# STM32U59x register map
File version: 0.2
Registers are 32-bit, read-write, reset 0x0 unless marked. A register's access mark holds for its fields unless they carry their own. Offsets are from the block's base; [hi:lo] are bit positions; {n}, {i} and the like mark numbered series.

## GPIOA — General-purpose I/Os
Base 0x42020000
Same registers: SEC_GPIOA 0x52020000
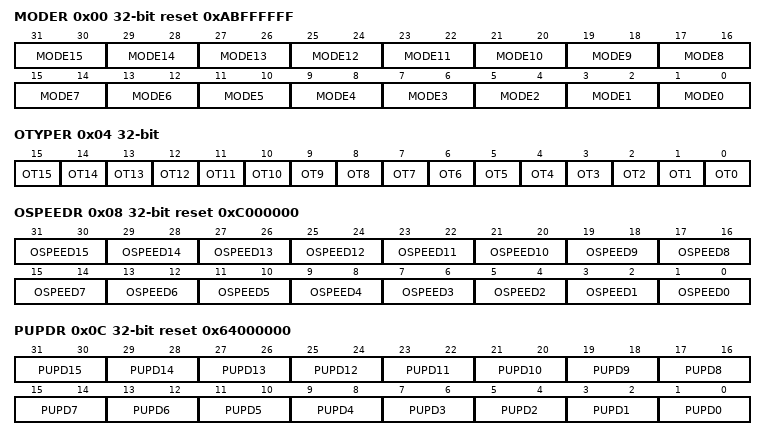
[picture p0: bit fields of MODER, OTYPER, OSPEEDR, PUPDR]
0x00 MODER reset 0xABFFFFFF — GPIO port mode register
  [2n+1:2n] MODE{n} (n=0..15) — Port x configuration bits (y = 0..15)
0x04 OTYPER — GPIO port output type register
  [n] OT{n} (n=0..15) — Port x configuration bits (y = 0..15)
0x08 OSPEEDR reset 0xC000000 — GPIO port output speed register
  [2n+1:2n] OSPEED{n} (n=0..15) — Port x configuration bits (y = 0..15)
0x0C PUPDR reset 0x64000000 — GPIO port pull-up/pull-down register
  [2n+1:2n] PUPD{n} (n=0..15) — Port x configuration bits (y = 0..15)
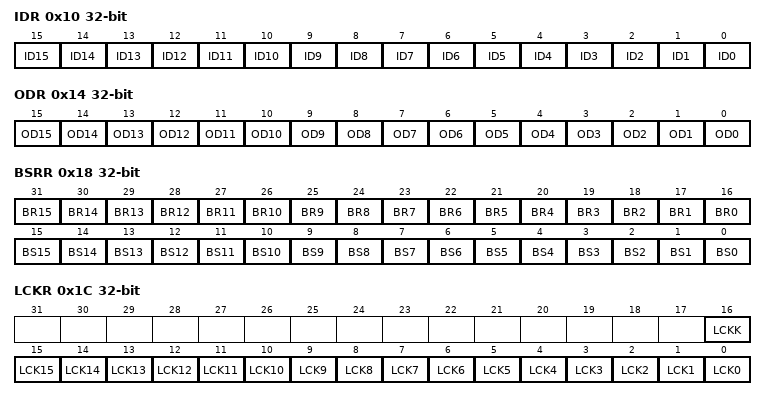
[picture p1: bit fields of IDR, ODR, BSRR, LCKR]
0x10 IDR ro — GPIO port input data register
  [n] ID{n} (n=0..15) — Port input data (y = 0..15)
0x14 ODR — GPIO port output data register
  [n] OD{n} (n=0..15) — Port output data (y = 0..15)
0x18 BSRR wo — GPIO port bit set/reset register
  [n+16] BR{n} (n=1..15) — Port x reset bit y (y = 0..15)
  [16] BR0 — Port x set bit y (y= 0..15)
  [n] BS{n} (n=0..15) — Port x set bit y (y= 0..15)
0x1C LCKR — GPIO port configuration lock register
  [16] LCKK — Lock key
  [n] LCK{n} (n=0..15) — Port x lock bit y (y= 0..15)
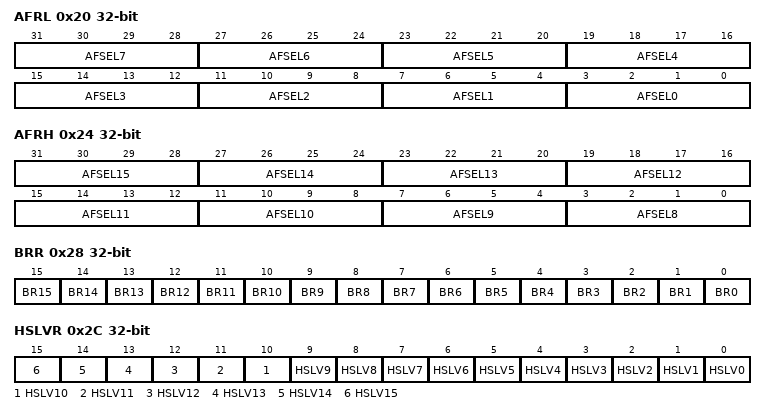
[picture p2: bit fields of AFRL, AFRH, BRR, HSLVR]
0x20 AFRL — GPIO alternate function low register
  [4n+3:4n] AFSEL{n} (n=0..7) — Alternate function selection for port x bit y (y = 0..7)
0x24 AFRH — GPIO alternate function high register
  [4n-29:4n-32] AFSEL{n} (n=8..15) — Alternate function selection for port x bit y (y = 8..15)
0x28 BRR wo — GPIO port bit reset register
  [n] BR{n} (n=0..15) — Port x reset IO pin y
0x2C HSLVR — GPIO high-speed low-voltage register
  [n] HSLV{n} (n=0..15) — Port x high-speed low-voltage configuration (y= 15 to 0)
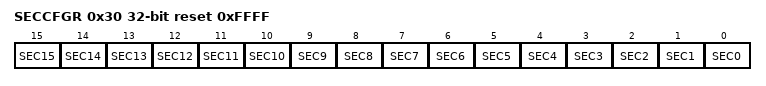
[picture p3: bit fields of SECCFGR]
0x30 SECCFGR wo reset 0xFFFF — GPIO secure configuration register
  [n] SEC{n} (n=0..15) — I/O pin of Port x secure bit enable

## GPIOB — General-purpose I/Os
Base 0x42020400
Same registers: SEC_GPIOB 0x52020400
Registers as GPIOA; these are added or differ:
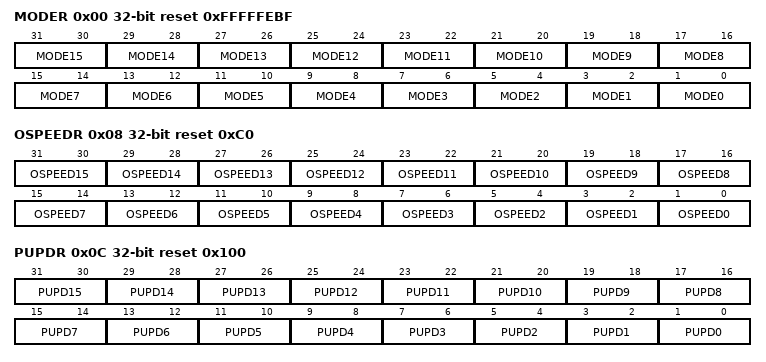
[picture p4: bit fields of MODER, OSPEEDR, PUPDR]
0x00 MODER reset 0xFFFFFEBF — GPIO port mode register
  [2n+1:2n] MODE{n} (n=0..15) — Port x configuration bits (y = 0..15)
0x08 OSPEEDR reset 0xC0 — GPIO port output speed register
  [2n+1:2n] OSPEED{n} (n=0..15) — Port x configuration bits (y = 0..15)
0x0C PUPDR reset 0x100 — GPIO port pull-up/pull-down register
  [2n+1:2n] PUPD{n} (n=0..15) — Port x configuration bits (y = 0..15)

## GPIOC — General-purpose I/Os
Base 0x42020800
Same registers: GPIOD 0x42020C00, GPIOE 0x42021000, GPIOF 0x42021400, GPIOG 0x42021800, GPIOH 0x42021C00, SEC_GPIOC 0x52020800, SEC_GPIOD 0x52020C00, SEC_GPIOE 0x52021000, SEC_GPIOF 0x52021400, SEC_GPIOG 0x52021800, SEC_GPIOH 0x52021C00
Registers as GPIOA; these are added or differ:
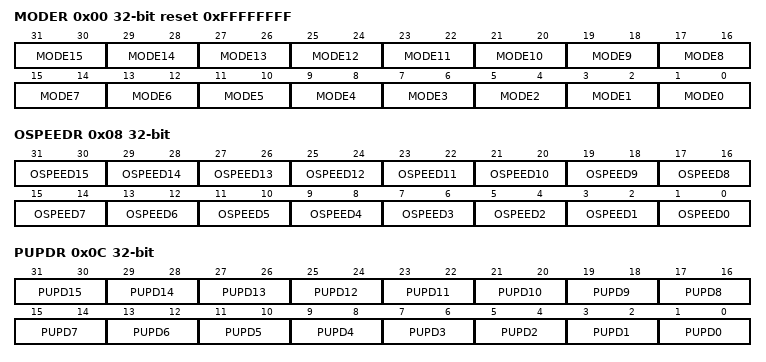
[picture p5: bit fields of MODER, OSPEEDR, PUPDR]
0x00 MODER reset 0xFFFFFFFF — GPIO port mode register
  [2n+1:2n] MODE{n} (n=0..15) — Port x configuration bits (y = 0..15)
0x08 OSPEEDR — GPIO port output speed register
  [2n+1:2n] OSPEED{n} (n=0..15) — Port x configuration bits (y = 0..15)
0x0C PUPDR — GPIO port pull-up/pull-down register
  [2n+1:2n] PUPD{n} (n=0..15) — Port x configuration bits (y = 0..15)

## GPIOJ — General-purpose I/Os
Base 0x42022400
Same registers: SEC_GPIOJ 0x52022400
Registers as GPIOA; these are added or differ:
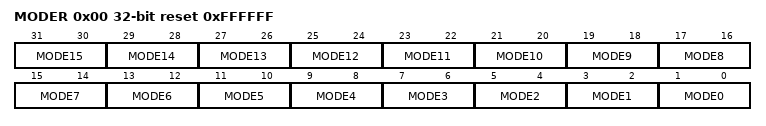
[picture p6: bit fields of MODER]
0x00 MODER reset 0xFFFFFF — GPIO port mode register
  [2n+1:2n] MODE{n} (n=0..15) — Port x configuration bits (y = 0..15)

## GPIOI — General-purpose I/Os
Base 0x42022000
Same registers: SEC_GPIOI 0x52022000
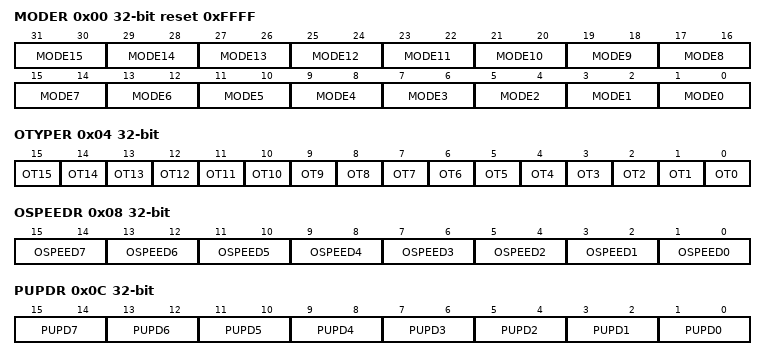
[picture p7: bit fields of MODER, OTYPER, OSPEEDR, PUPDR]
0x00 MODER reset 0xFFFF — GPIO port mode register
  [2n+1:2n] MODE{n} (n=0..15) — Port x configuration bits (y = 0..15)
0x04 OTYPER — GPIO port output type register
  [n] OT{n} (n=0..15) — Port x configuration bits (y = 0..15)
0x08 OSPEEDR — GPIO port output speed register
  [2n+1:2n] OSPEED{n} (n=0..7) — Port x configuration bits (y =7 .. 0)
0x0C PUPDR — GPIO port pull-up/pull-down register
  [2n+1:2n] PUPD{n} (n=0..7) — Port x configuration bits (y =7 .. 0)
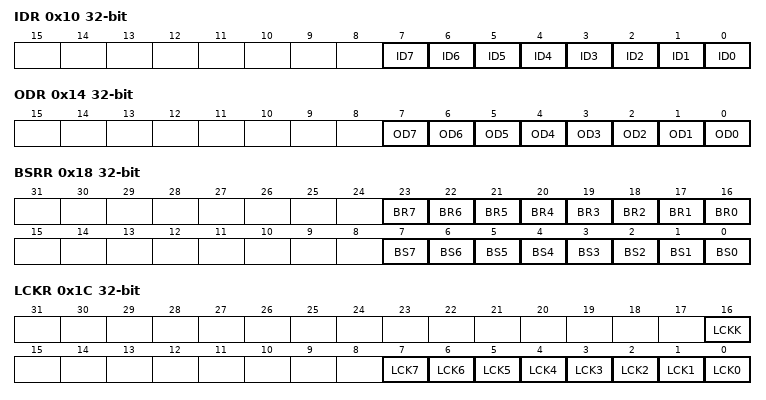
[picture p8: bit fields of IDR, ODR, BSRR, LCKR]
0x10 IDR ro — GPIO port input data register
  [n] ID{n} (n=0..7) — Port input data (y = 0..7)
0x14 ODR — GPIO port output data register
  [n] OD{n} (n=0..7) — Port output data (y = 0..7)
0x18 BSRR wo — GPIO port bit set/reset register
  [n+16] BR{n} (n=1..7) — Port x reset bit y (y = 0..7)
  [16] BR0 — Port x set bit y (y= 0..7)
  [n] BS{n} (n=0..7) — Port x set bit y (y= 0..7)
0x1C LCKR — GPIO port configuration lock register
  [16] LCKK — Lock key
  [n] LCK{n} (n=0..7) — Port x lock bit y (y= 0..15)
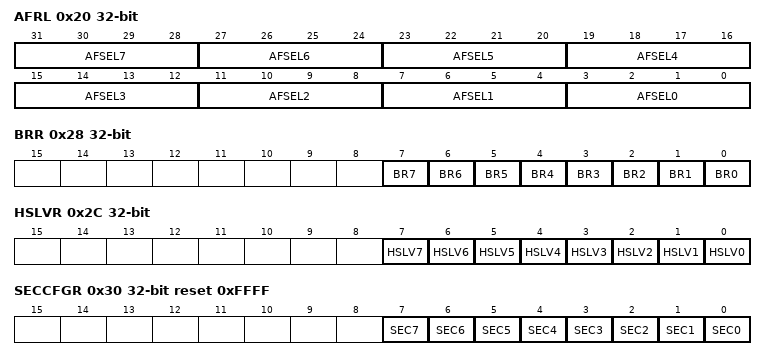
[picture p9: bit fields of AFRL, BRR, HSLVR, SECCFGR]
0x20 AFRL — GPIO alternate function low register
  [4n+3:4n] AFSEL{n} (n=0..7) — Alternate function selection for port x bit y (y = 0..7)
0x28 BRR wo — GPIO port bit reset register
  [n] BR{n} (n=0..7) — Port x reset IO pin y
0x2C HSLVR — GPIO high-speed low-voltage register
  [n] HSLV{n} (n=0..7) — Port x high-speed low-voltage configuration (y= 7 to 0)
0x30 SECCFGR wo reset 0xFFFF — GPIO secure configuration register
  [n] SEC{n} (n=0..7) — I/O pin of Port x secure bit enable

## Notices in the file
Copyright (c) 2020 STMicroelectronics.
SPDX-License-Identifier: Apache-2.0
Licensed under the Apache License, Version 2.0 (the "License");
you may not use this file except in compliance with the License.
You may obtain a copy of the License at
http://www.apache.org/licenses/LICENSE-2.0
Unless required by applicable law or agreed to in writing, software
distributed under the License is distributed on an "AS IS" BASIS,
WITHOUT WARRANTIES OR CONDITIONS OF ANY KIND, either express or implied.
See the License for the specific language governing permissions and
limitations under the License.
